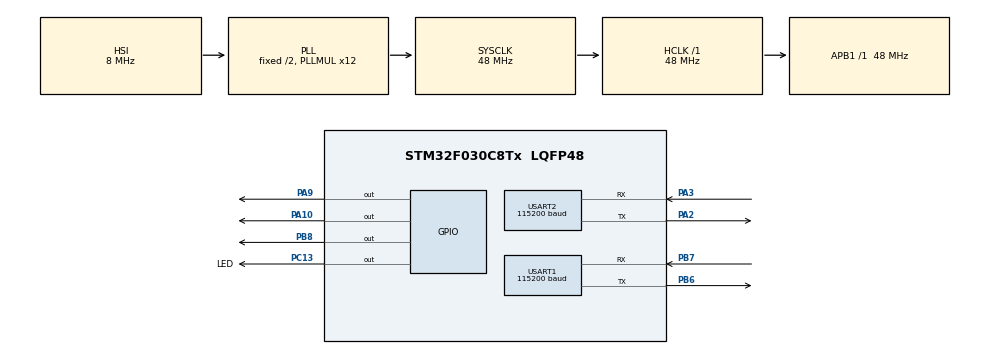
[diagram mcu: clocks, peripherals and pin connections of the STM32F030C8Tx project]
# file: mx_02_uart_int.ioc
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Dma.Request0=USART2_TX
Dma.Request1=USART2_RX
Dma.Request2=USART1_TX
Dma.USART1_TX.2.Direction=DMA_MEMORY_TO_PERIPH
Dma.USART1_TX.2.Instance=DMA1_Channel2
Dma.USART1_TX.2.MemDataAlignment=DMA_MDATAALIGN_BYTE
Dma.USART1_TX.2.MemInc=DMA_MINC_ENABLE
Dma.USART1_TX.2.Mode=DMA_NORMAL
Dma.USART1_TX.2.PeriphDataAlignment=DMA_PDATAALIGN_BYTE
Dma.USART1_TX.2.PeriphInc=DMA_PINC_DISABLE
Dma.USART1_TX.2.Priority=DMA_PRIORITY_LOW
Dma.USART2_RX.1.Direction=DMA_PERIPH_TO_MEMORY
Dma.USART2_RX.1.Instance=DMA1_Channel5
Dma.USART2_RX.1.MemDataAlignment=DMA_MDATAALIGN_BYTE
Dma.USART2_RX.1.MemInc=DMA_MINC_ENABLE
Dma.USART2_RX.1.Mode=DMA_NORMAL
Dma.USART2_RX.1.PeriphDataAlignment=DMA_PDATAALIGN_BYTE
Dma.USART2_RX.1.PeriphInc=DMA_PINC_DISABLE
Dma.USART2_RX.1.Priority=DMA_PRIORITY_LOW
Dma.USART2_TX.0.Direction=DMA_MEMORY_TO_PERIPH
Dma.USART2_TX.0.Instance=DMA1_Channel4
Dma.USART2_TX.0.MemDataAlignment=DMA_MDATAALIGN_BYTE
Dma.USART2_TX.0.MemInc=DMA_MINC_ENABLE
Dma.USART2_TX.0.Mode=DMA_NORMAL
Dma.USART2_TX.0.PeriphDataAlignment=DMA_PDATAALIGN_BYTE
Dma.USART2_TX.0.PeriphInc=DMA_PINC_DISABLE
Dma.USART2_TX.0.Priority=DMA_PRIORITY_LOW
Mcu.Family=STM32F0
Mcu.Name=STM32F030C8Tx
Mcu.Package=LQFP48
NVIC.DMA1_Channel2_3_IRQn=true\:0\:0\:false\:false\:true
NVIC.DMA1_Channel4_5_IRQn=true\:0\:0\:false\:false\:true
NVIC.USART1_IRQn=true\:0\:0\:false\:false\:true
NVIC.USART2_IRQn=true\:0\:0\:false\:false\:true
PA10.Signal=GPIO_Output
PA2.Mode=Asynchronous
PA2.Signal=USART2_TX
PA3.Mode=Asynchronous
PA3.Signal=USART2_RX
PA9.Signal=GPIO_Output
PB6.Mode=Asynchronous
PB6.Signal=USART1_TX
PB7.Mode=Asynchronous
PB7.Signal=USART1_RX
PB8.GPIO_PuPd=GPIO_PULLUP
PB8.Signal=GPIO_Output
PC13.GPIO_Label=LED
PC13.GPIO_PuPd=GPIO_PULLUP
PC13.Signal=GPIO_Output
ProjectManager.HeapSize=0x200
ProjectManager.StackSize=0x400
ProjectManager.TargetToolchain=MDK-ARM V5
RCC.AHBFreq_Value=48000000
RCC.APB1Freq_Value=48000000
RCC.APB1TimFreq_Value=48000000
RCC.HCLKFreq_Value=48000000
RCC.PLLMUL=RCC_PLL_MUL12
RCC.SYSCLKFreq_VALUE=48000000
RCC.SYSCLKSource=RCC_SYSCLKSOURCE_PLLCLK
USART1.BaudRate=115200
USART2.BaudRate=115200
board=mx_02_uart_int

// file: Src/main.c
/**
  ******************************************************************************
  * File Name          : main.c
  * Description        : Main program body
  ******************************************************************************
  *
  * COPYRIGHT(c) 2016 STMicroelectronics
  *
  * Redistribution and use in source and binary forms, with or without modification,
  * are permitted provided that the following conditions are met:
  *   1. Redistributions of source code must retain the above copyright notice,
  *      this list of conditions and the following disclaimer.
  *   2. Redistributions in binary form must reproduce the above copyright notice,
  *      this list of conditions and the following disclaimer in the documentation
  *      and/or other materials provided with the distribution.
  *   3. Neither the name of STMicroelectronics nor the names of its contributors
  *      may be used to endorse or promote products derived from this software
  *      without specific prior written permission.
  *
  * THIS SOFTWARE IS PROVIDED BY THE COPYRIGHT HOLDERS AND CONTRIBUTORS "AS IS"
  * AND ANY EXPRESS OR IMPLIED WARRANTIES, INCLUDING, BUT NOT LIMITED TO, THE
  * IMPLIED WARRANTIES OF MERCHANTABILITY AND FITNESS FOR A PARTICULAR PURPOSE ARE
  * DISCLAIMED. IN NO EVENT SHALL THE COPYRIGHT HOLDER OR CONTRIBUTORS BE LIABLE
  * FOR ANY DIRECT, INDIRECT, INCIDENTAL, SPECIAL, EXEMPLARY, OR CONSEQUENTIAL
  * DAMAGES (INCLUDING, BUT NOT LIMITED TO, PROCUREMENT OF SUBSTITUTE GOODS OR
  * SERVICES; LOSS OF USE, DATA, OR PROFITS; OR BUSINESS INTERRUPTION) HOWEVER
  * CAUSED AND ON ANY THEORY OF LIABILITY, WHETHER IN CONTRACT, STRICT LIABILITY,
  * OR TORT (INCLUDING NEGLIGENCE OR OTHERWISE) ARISING IN ANY WAY OUT OF THE USE
  * OF THIS SOFTWARE, EVEN IF ADVISED OF THE POSSIBILITY OF SUCH DAMAGE.
  *
  ******************************************************************************
  */
#include "main.h"
#include "stm32f0xx_hal.h"
#include "dma.h"
#include "usart.h"
#include "gpio.h"
#include "terminal.h"

/* USER CODE BEGIN PV */
/* Private variables ---------------------------------------------------------*/

/* USER CODE END PV */

void SystemClock_Config(void);
void Error_Handler(void);

/* USER CODE BEGIN PFP */
/* Private function prototypes -----------------------------------------------*/

/* USER CODE END PFP */

/* USER CODE BEGIN 0 */
#if 0
void terminal1_data_process(uint8_t data)
{
		HAL_UART_Transmit(&huart1, &data, 1, 1);
}
//#else
void terminal1_data_process(uint8_t data)
{
		macro_queue_write(data,cache1_terminal);
}
#endif
/* USER CODE END 0 */

int main(void)
{

	uint8_t _byte=0;

  /* MCU Configuration----------------------------------------------------------*/

  /* Reset of all peripherals, Initializes the Flash interface and the Systick. */
  HAL_Init();

  /* Configure the system clock */
  SystemClock_Config();

  /* Initialize all configured peripherals */
  MX_GPIO_Init();
  MX_DMA_Init();
  MX_USART2_UART_Init();
  MX_USART1_UART_Init();

  /* USER CODE BEGIN 2 */
	HAL_UART_Transmit_DMA(&huart1, "Hello\r\n", 7);
	HAL_Delay(1);
	HAL_UART_Transmit_DMA(&huart2, "world\r\n", 7);
  /* USER CODE END 2 */
	//HAL_UART_Receive_IT(&huart1, &pData, 1);
	__HAL_UART_ENABLE_IT(&huart1, UART_IT_RXNE);

  /* Infinite loop */
  /* USER CODE BEGIN WHILE */
  while (1)
  {
			if(0==cache_queue_read_byte(&cache1_terminal, &_byte))
			{
					HAL_UART_Transmit(&huart1, &_byte, 1, 1);
			}
			HAL_Delay(1);
  }
  /* USER CODE END 3 */

}

/** System Clock Configuration
*/
void SystemClock_Config(void)
{

  RCC_OscInitTypeDef RCC_OscInitStruct;
  RCC_ClkInitTypeDef RCC_ClkInitStruct;
  RCC_PeriphCLKInitTypeDef PeriphClkInit;

    /**Initializes the CPU, AHB and APB busses clocks
    */
  RCC_OscInitStruct.OscillatorType = RCC_OSCILLATORTYPE_HSI;
  RCC_OscInitStruct.HSIState = RCC_HSI_ON;
  RCC_OscInitStruct.HSICalibrationValue = 16;
  RCC_OscInitStruct.PLL.PLLState = RCC_PLL_ON;
  RCC_OscInitStruct.PLL.PLLSource = RCC_PLLSOURCE_HSI;
  RCC_OscInitStruct.PLL.PLLMUL = RCC_PLL_MUL12;
  RCC_OscInitStruct.PLL.PREDIV = RCC_PREDIV_DIV1;
  if (HAL_RCC_OscConfig(&RCC_OscInitStruct) != HAL_OK)
  {
    Error_Handler();
  }

    /**Initializes the CPU, AHB and APB busses clocks
    */
  RCC_ClkInitStruct.ClockType = RCC_CLOCKTYPE_HCLK|RCC_CLOCKTYPE_SYSCLK
                              |RCC_CLOCKTYPE_PCLK1;
  RCC_ClkInitStruct.SYSCLKSource = RCC_SYSCLKSOURCE_PLLCLK;
  RCC_ClkInitStruct.AHBCLKDivider = RCC_SYSCLK_DIV1;
  RCC_ClkInitStruct.APB1CLKDivider = RCC_HCLK_DIV1;

  if (HAL_RCC_ClockConfig(&RCC_ClkInitStruct, FLASH_LATENCY_1) != HAL_OK)
  {
    Error_Handler();
  }

  PeriphClkInit.PeriphClockSelection = RCC_PERIPHCLK_USART1;
  PeriphClkInit.Usart1ClockSelection = RCC_USART1CLKSOURCE_PCLK1;
  if (HAL_RCCEx_PeriphCLKConfig(&PeriphClkInit) != HAL_OK)
  {
    Error_Handler();
  }

    /**Configure the Systick interrupt time
    */
  HAL_SYSTICK_Config(HAL_RCC_GetHCLKFreq()/1000);

    /**Configure the Systick
    */
  HAL_SYSTICK_CLKSourceConfig(SYSTICK_CLKSOURCE_HCLK);

  /* SysTick_IRQn interrupt configuration */
  HAL_NVIC_SetPriority(SysTick_IRQn, 0, 0);
}

void Error_Handler(void)
{
  while(1)
  {
  }
}

/************************ (C) COPYRIGHT STMicroelectronics *****END OF FILE****/
